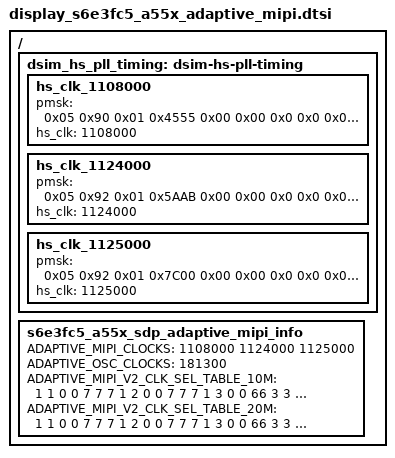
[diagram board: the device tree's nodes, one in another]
/*
 * SAMSUNG Panel Device Tree Source
 *
 * Copyright (c) Samsung Electronics Co., Ltd.
 *		http://www.samsung.com
 *
 * This program is free software; you can redistribute it and/or modify
 * it under the terms of the GNU General Public License version 2 as
 * published by the Free Software Foundation.
 */

#include <dt-bindings/display/rf-band-id.h>

/ {
	fragment@freq_hop {
		target-path = "/";
		__overlay__ {
			dsim_hs_pll_timing: dsim-hs-pll-timing {
				hs_clk_1108000 {
					pmsk = <
						0x05 0x90 0x01 0x4555 /* p m s k */
						0x00 0x00 0x0 0x0
						0x0 0x0 0x0 0x0
						0x0 0x0
						>;
					hs_clk = <1108000>;
				};

				hs_clk_1124000 {
					pmsk = <
						0x05 0x92 0x01 0x5AAB /* p m s k */
						0x00 0x00 0x0 0x0
						0x0 0x0 0x0 0x0
						0x0 0x0
						>;
					hs_clk = <1124000>;
				};

				hs_clk_1125000 {
					pmsk = <
						0x05 0x92 0x01 0x7C00 /* p m s k */
						0x00 0x00 0x0 0x0
						0x0 0x0 0x0 0x0
						0x0 0x0
						>;
					hs_clk = <1125000>;
				};
			};

			s6e3fc5_a55x_sdp_adaptive_mipi_info:
			s6e3fc5_a55x_sdp_adaptive_mipi_info {
				/* TABLE: ADAPTIVE MIPI V2: MIPI CLOCKS [kbps] */
				ADAPTIVE_MIPI_CLOCKS = <
					  1108000
					  1124000
					  1125000
				>;

				/* TABLE: ADAPTIVE MIPI V2: OSC CLOCKS [khz] */
				ADAPTIVE_OSC_CLOCKS = <
					  181300
				>;

				/* TABLE: ADAPTIVE MIPI V2: TABLE_10M */
				/* RAT BAND FROM END RATING_A RATING_B RATING_C */
				ADAPTIVE_MIPI_V2_CLK_SEL_TABLE_10M = <
					1	1	0	0	7	7	7
					1	2	0	0	7	7	7
					1	3	0	0	66	3	3
					1	4	0	0	3	0	0
					2	11	10562	10572	0	60	60
					2	11	10573	10581	0	0	60
					2	11	10582	10583	0	0	0
					2	11	10584	10653	3	0	0
					2	11	10654	10736	0	0	0
					2	11	10737	10746	0	3	0
					2	11	10747	10806	0	3	3
					2	11	10807	10814	0	0	3
					2	11	10815	10816	3	0	3
					2	11	10817	10838	3	0	0
					2	12	9662	9729	60	0	0
					2	12	9730	9799	0	0	0
					2	12	9800	9808	0	60	0
					2	12	9809	9869	0	60	60
					2	12	9870	9878	0	0	60
					2	12	9879	9890	0	0	0
					2	12	9891	9938	3	0	0
					2	13	1162	1162	60	0	0
					2	13	1163	1222	0	0	0
					2	13	1223	1230	0	60	0
					2	13	1231	1292	0	60	60
					2	13	1293	1300	0	0	60
					2	13	1301	1323	0	0	0
					2	13	1324	1393	3	0	0
					2	13	1394	1456	0	0	0
					2	13	1457	1464	0	3	0
					2	13	1465	1513	0	3	3
					2	14	1537	1547	0	60	60
					2	14	1548	1556	0	0	60
					2	14	1557	1558	0	0	0
					2	14	1559	1628	3	0	0
					2	14	1629	1711	0	0	0
					2	14	1712	1721	0	3	0
					2	14	1722	1738	0	3	3
					2	15	4357	4414	7	0	0
					2	15	4415	4418	7	7	0
					2	15	4419	4420	7	7	7
					2	15	4421	4458	0	7	7
					2	16	4387	4413	7	0	0
					2	17	2237	2247	0	2	2
					2	17	2248	2273	40	2	2
					2	17	2274	2284	40	0	2
					2	17	2285	2317	40	0	0
					2	17	2318	2437	0	0	0
					2	17	2438	2449	0	40	0
					2	17	2450	2478	0	40	40
					2	17	2479	2507	2	40	40
					2	17	2508	2519	2	0	40
					2	17	2520	2548	2	0	0
					2	17	2549	2563	0	0	0
					2	18	2937	2948	7	0	0
					2	18	2949	2951	7	7	0
					2	18	2952	2952	0	7	0
					2	18	2953	3018	0	7	7
					2	18	3019	3022	0	0	7
					2	18	3023	3088	0	0	0
					2	29	712	739	7	0	0
					2	29	740	743	7	7	0
					2	29	744	745	7	7	7
					2	29	746	763	0	7	7
					3	91	0	44	0	60	60
					3	91	45	63	0	0	60
					3	91	64	66	0	0	0
					3	91	67	206	3	0	0
					3	91	207	373	0	0	0
					3	91	374	392	0	3	0
					3	91	393	513	0	3	3
					3	91	514	528	0	0	3
					3	91	529	532	3	0	3
					3	91	533	599	3	0	0
					3	92	600	619	0	0	0
					3	92	620	759	60	0	0
					3	92	760	899	0	0	0
					3	92	900	917	0	60	0
					3	92	918	1039	0	60	60
					3	92	1040	1057	0	0	60
					3	92	1058	1081	0	0	0
					3	92	1082	1199	3	0	0
					3	93	1200	1224	60	0	0
					3	93	1225	1344	0	0	0
					3	93	1345	1361	0	60	0
					3	93	1362	1484	0	60	60
					3	93	1485	1501	0	0	60
					3	93	1502	1546	0	0	0
					3	93	1547	1686	3	0	0
					3	93	1687	1813	0	0	0
					3	93	1814	1829	0	3	0
					3	93	1830	1949	0	3	3
					3	94	1950	1994	0	60	60
					3	94	1995	2013	0	0	60
					3	94	2014	2016	0	0	0
					3	94	2017	2156	3	0	0
					3	94	2157	2323	0	0	0
					3	94	2324	2342	0	3	0
					3	94	2343	2399	0	3	3
					3	95	2400	2411	0	0	0
					3	95	2412	2538	7	0	0
					3	95	2539	2546	7	7	0
					3	95	2547	2551	7	7	7
					3	95	2552	2649	0	7	7
					3	97	2750	2794	0	2	2
					3	97	2795	2846	40	2	2
					3	97	2847	2869	40	0	2
					3	97	2870	2934	40	0	0
					3	97	2935	3174	0	0	0
					3	97	3175	3198	0	40	0
					3	97	3199	3256	0	40	40
					3	97	3257	3314	2	40	40
					3	97	3315	3338	2	0	40
					3	97	3339	3396	2	0	0
					3	97	3397	3449	0	0	0
					3	98	3450	3496	7	0	0
					3	98	3497	3503	7	7	0
					3	98	3504	3504	0	7	0
					3	98	3505	3636	0	7	7
					3	98	3637	3644	0	0	7
					3	98	3645	3799	0	0	0
					3	102	5010	5036	0	0	0
					3	102	5037	5143	7	0	0
					3	102	5144	5149	7	7	0
					3	102	5150	5176	7	7	7
					3	102	5177	5179	0	7	7
					3	103	5180	5279	0	7	7
					3	104	5280	5379	0	0	0
					3	107	5730	5813	7	0	0
					3	107	5814	5819	7	7	0
					3	107	5820	5846	7	7	7
					3	107	5847	5849	0	7	7
					3	108	5850	5951	0	0	0
					3	108	5952	5999	7	0	0
					3	109	6000	6078	7	0	0
					3	109	6079	6086	7	7	0
					3	109	6087	6091	7	7	7
					3	109	6092	6149	0	7	7
					3	110	6150	6158	7	7	7
					3	110	6159	6271	0	7	7
					3	110	6272	6278	0	0	7
					3	110	6279	6449	0	0	0
					3	111	6450	6547	0	3	3
					3	111	6548	6560	0	0	3
					3	111	6561	6599	0	0	0
					3	115	8040	8059	0	0	0
					3	115	8060	8199	60	0	0
					3	115	8200	8339	0	0	0
					3	115	8340	8357	0	60	0
					3	115	8358	8479	0	60	60
					3	115	8480	8497	0	0	60
					3	115	8498	8521	0	0	0
					3	115	8522	8661	3	0	0
					3	115	8662	8689	0	0	0
					3	116	8690	8801	0	0	0
					3	116	8802	8928	7	0	0
					3	116	8929	8936	7	7	0
					3	116	8937	8941	7	7	7
					3	116	8942	9039	0	7	7
					3	118	9210	9408	0	0	0
					3	118	9409	9521	7	0	0
					3	118	9522	9528	7	7	0
					3	118	9529	9548	7	7	7
					3	118	9549	9659	0	7	7
					3	119	9660	9769	0	0	0
					3	120	9770	9777	40	0	2
					3	120	9778	9869	40	0	0
					3	122	9920	9988	0	3	3
					3	122	9989	10001	0	0	3
					3	122	10002	10103	0	0	0
					3	122	10104	10243	3	0	0
					3	122	10244	10316	0	0	0
					3	122	10317	10329	0	3	0
					3	122	10330	10359	0	3	3
					3	124	36200	36308	0	3	3
					3	124	36309	36326	0	0	3
					3	124	36327	36343	0	0	0
					3	124	36344	36349	3	0	0
					3	128	37750	37761	0	2	0
					3	128	37762	37833	0	2	2
					3	128	37834	37878	2	2	2
					3	128	37879	37901	2	0	2
					3	128	37902	37973	2	0	0
					3	128	37974	38206	0	0	0
					3	128	38207	38229	0	2	0
					3	128	38230	38249	0	2	2
					3	129	38250	38253	0	3	3
					3	129	38254	38269	0	0	3
					3	129	38270	38308	0	0	0
					3	129	38309	38448	3	0	0
					3	129	38449	38581	0	0	0
					3	129	38582	38598	0	3	0
					3	129	38599	38649	0	3	3
					3	130	38650	38663	0	2	2
					3	130	38664	38668	2	2	2
					3	130	38669	38688	2	0	2
					3	130	38689	38803	2	0	0
					3	130	38804	38996	0	0	0
					3	130	38997	39017	0	2	0
					3	130	39018	39124	0	2	2
					3	130	39125	39136	40	2	2
					3	130	39137	39157	40	0	2
					3	130	39158	39264	40	0	0
					3	130	39265	39464	0	0	0
					3	130	39465	39486	0	40	0
					3	130	39487	39586	0	40	40
					3	130	39587	39604	2	40	40
					3	130	39605	39626	2	0	40
					3	130	39627	39649	2	0	0
					3	131	39650	39689	40	0	0
					3	131	39690	39909	0	0	0
					3	131	39910	39932	0	40	0
					3	131	39933	40011	0	40	40
					3	131	40012	40049	2	40	40
					3	131	40050	40072	2	0	40
					3	131	40073	40151	2	0	0
					3	131	40152	40378	0	0	0
					3	131	40379	40401	0	2	0
					3	131	40402	40473	0	2	2
					3	131	40474	40518	2	2	2
					3	131	40519	40541	2	0	2
					3	131	40542	40613	2	0	0
					3	131	40614	40846	0	0	0
					3	131	40847	40869	0	2	0
					3	131	40870	40934	0	2	2
					3	131	40935	40986	40	2	2
					3	131	40987	41009	40	0	2
					3	131	41010	41074	40	0	0
					3	131	41075	41314	0	0	0
					3	131	41315	41338	0	40	0
					3	131	41339	41396	0	40	40
					3	131	41397	41454	2	40	40
					3	131	41455	41478	2	0	40
					3	131	41479	41536	2	0	0
					3	131	41537	41589	0	0	0
					3	132	41590	41683	0	0	0
					3	132	41684	41708	2	0	0
					3	132	41709	41738	2	2	0
					3	132	41739	41823	2	2	2
					3	132	41824	41848	0	2	2
					3	132	41849	41878	0	0	2
					3	132	41879	42145	0	0	0
					3	132	42146	42176	40	0	0
					3	132	42177	42207	40	2	0
					3	132	42208	42285	40	2	2
					3	132	42286	42316	0	2	2
					3	132	42317	42347	0	0	2
					3	132	42348	42606	0	0	0
					3	132	42607	42645	2	0	0
					3	132	42646	42676	2	40	0
					3	132	42677	42746	2	40	40
					3	132	42747	42785	0	40	40
					3	132	42786	42816	0	0	40
					3	132	42817	43068	0	0	0
					3	132	43069	43113	2	0	0
					3	132	43114	43145	2	2	0
					3	132	43146	43208	2	2	2
					3	132	43209	43253	0	2	2
					3	132	43254	43285	0	0	2
					3	132	43286	43530	0	0	0
					3	132	43531	43581	40	0	0
					3	132	43582	43589	40	2	0
					3	138	55240	55263	2	0	0
					3	138	55264	55295	2	2	0
					3	138	55296	55358	2	2	2
					3	138	55359	55403	0	2	2
					3	138	55404	55435	0	0	2
					3	138	55436	55680	0	0	0
					3	138	55681	55731	40	0	0
					3	138	55732	55763	40	2	0
					3	138	55764	55820	40	2	2
					3	138	55821	55871	0	2	2
					3	138	55872	55903	0	0	2
					3	138	55904	56141	0	0	0
					3	138	56142	56200	2	0	0
					3	138	56201	56232	2	40	0
					3	138	56233	56281	2	40	40
					3	138	56282	56340	0	40	40
					3	138	56341	56372	0	0	40
					3	138	56373	56603	0	0	0
					3	138	56604	56668	2	0	0
					3	138	56669	56701	2	2	0
					3	138	56702	56739	2	2	2
					3	156	66436	66480	0	60	60
					3	156	66481	66499	0	0	60
					3	156	66500	66502	0	0	0
					3	156	66503	66642	3	0	0
					3	156	66643	66809	0	0	0
					3	156	66810	66828	0	3	0
					3	156	66829	66949	0	3	3
					3	156	66950	66964	0	0	3
					3	156	66965	66968	3	0	3
					3	156	66969	67104	3	0	0
					3	156	67105	67277	0	0	0
					3	156	67278	67297	0	3	0
					3	156	67298	67335	0	3	3
					3	161	68586	68809	0	0	0
					3	161	68810	68902	7	0	0
					3	161	68903	68908	7	7	0
					3	161	68909	68935	7	7	7
					4	51	0	0	0	3	3
					4	52	0	0	3	3	3
					4	53	0	0	0	3	6
					4	54	0	0	0	6	6
					4	55	0	0	48	2	4
					4	56	0	0	3	6	6
					5	61	0	0	7	7	7
					5	62	0	0	3	0	0
					5	71	0	0	0	0	0
					7	256	422000	422880	0	60	60
					7	256	422881	423260	0	0	60
					7	256	423261	423320	0	0	0
					7	256	423321	426120	3	0	0
					7	256	426121	429460	0	0	0
					7	256	429461	429840	0	3	0
					7	256	429841	432260	0	3	3
					7	256	432261	432560	0	0	3
					7	256	432561	432640	3	0	3
					7	256	432641	433980	3	0	0
					7	257	386000	386380	0	0	0
					7	257	386381	389180	60	0	0
					7	257	389181	391980	0	0	0
					7	257	391981	392340	0	60	0
					7	257	392341	394780	0	60	60
					7	257	394781	395140	0	0	60
					7	257	395141	395620	0	0	0
					7	257	395621	397980	3	0	0
					7	258	361000	361480	60	0	0
					7	258	361481	363880	0	0	0
					7	258	363881	364220	0	60	0
					7	258	364221	366680	0	60	60
					7	258	366681	367020	0	0	60
					7	258	367021	367920	0	0	0
					7	258	367921	370720	3	0	0
					7	258	370721	373260	0	0	0
					7	258	373261	373580	0	3	0
					7	258	373581	375980	0	3	3
					7	260	173800	174020	0	0	0
					7	260	174021	176560	7	0	0
					7	260	176561	176720	7	7	0
					7	260	176721	176820	7	7	7
					7	260	176821	178780	0	7	7
					7	262	524000	524880	0	2	2
					7	262	524881	525920	40	2	2
					7	262	525921	526380	40	0	2
					7	262	526381	527680	40	0	0
					7	262	527681	532480	0	0	0
					7	262	532481	532960	0	40	0
					7	262	532961	534120	0	40	40
					7	262	534121	535280	2	40	40
					7	262	535281	535760	2	0	40
					7	262	535761	536920	2	0	0
					7	262	536921	538000	0	0	0
					7	263	185000	185920	7	0	0
					7	263	185921	186060	7	7	0
					7	263	186061	186080	0	7	0
					7	263	186081	188720	0	7	7
					7	263	188721	188880	0	0	7
					7	263	188881	191980	0	0	0
					7	267	145800	146320	0	0	0
					7	267	146321	148460	7	0	0
					7	267	148461	148580	7	7	0
					7	267	148581	149120	7	7	7
					7	267	149121	149200	0	7	7
					7	268	149200	151200	0	7	7
					7	269	151600	153580	0	0	0
					7	273	172000	174020	0	0	0
					7	273	174021	175000	7	0	0
					7	275	158200	158360	7	7	7
					7	275	158361	160620	0	7	7
					7	275	160621	160760	0	0	7
					7	275	160761	164180	0	0	0
					7	280	386000	386380	0	0	0
					7	280	386381	389180	60	0	0
					7	280	389181	391980	0	0	0
					7	280	391981	392340	0	60	0
					7	280	392341	394780	0	60	60
					7	280	394781	395140	0	0	60
					7	280	395141	395620	0	0	0
					7	280	395621	398420	3	0	0
					7	280	398421	398980	0	0	0
					7	281	171800	174020	0	0	0
					7	281	174021	176560	7	0	0
					7	281	176561	176720	7	7	0
					7	281	176721	176820	7	7	7
					7	281	176821	178800	0	7	7
					7	283	151600	155560	0	0	0
					7	283	155561	157820	7	0	0
					7	283	157821	157960	7	7	0
					7	283	157961	158360	7	7	7
					7	283	158361	160580	0	7	7
					7	284	143400	145580	0	0	0
					7	285	470000	470140	40	0	2
					7	285	470141	471980	40	0	0
					7	293	514000	514220	0	2	0
					7	293	514221	515660	0	2	2
					7	293	515661	516560	2	2	2
					7	293	516561	517020	2	0	2
					7	293	517021	518460	2	0	0
					7	293	518461	523120	0	0	0
					7	293	523121	523580	0	2	0
					7	293	523581	523980	0	2	2
					7	294	376000	376060	0	3	3
					7	294	376061	376380	0	0	3
					7	294	376381	377160	0	0	0
					7	294	377161	379960	3	0	0
					7	294	379961	382620	0	0	0
					7	294	382621	382960	0	3	0
					7	294	382961	384000	0	3	3
					7	295	460000	460260	0	2	2
					7	295	460261	460360	2	2	2
					7	295	460361	460760	2	0	2
					7	295	460761	463060	2	0	0
					7	295	463061	466920	0	0	0
					7	295	466921	467340	0	2	0
					7	295	467341	469480	0	2	2
					7	295	469481	469720	40	2	2
					7	295	469721	470140	40	0	2
					7	295	470141	472280	40	0	0
					7	295	472281	476280	0	0	0
					7	295	476281	476720	0	40	0
					7	295	476721	478720	0	40	40
					7	295	478721	479080	2	40	40
					7	295	479081	479520	2	0	40
					7	295	479521	480000	2	0	0
					7	296	499200	499980	40	0	0
					7	296	499981	504380	0	0	0
					7	296	504381	504840	0	40	0
					7	296	504841	506420	0	40	40
					7	296	506421	507180	2	40	40
					7	296	507181	507640	2	0	40
					7	296	507641	509220	2	0	0
					7	296	509221	513760	0	0	0
					7	296	513761	514220	0	2	0
					7	296	514221	515660	0	2	2
					7	296	515661	516560	2	2	2
					7	296	516561	517020	2	0	2
					7	296	517021	518460	2	0	0
					7	296	518461	523120	0	0	0
					7	296	523121	523580	0	2	0
					7	296	523581	524880	0	2	2
					7	296	524881	525920	40	2	2
					7	296	525921	526380	40	0	2
					7	296	526381	527680	40	0	0
					7	296	527681	532480	0	0	0
					7	296	532481	532960	0	40	0
					7	296	532961	534120	0	40	40
					7	296	534121	535280	2	40	40
					7	296	535281	535760	2	0	40
					7	296	535761	536920	2	0	0
					7	296	536921	537980	0	0	0
					7	303	636667	636807	1	0	0
					7	303	636808	637027	1	1	0
					7	303	637028	637447	1	1	1
					7	303	637448	637747	0	1	1
					7	303	637748	637947	0	0	1
					7	303	637948	639587	0	0	0
					7	303	639588	639927	20	0	0
					7	303	639928	640147	20	1	0
					7	303	640148	640527	20	1	1
					7	303	640528	640867	0	1	1
					7	303	640868	641087	0	0	1
					7	303	641088	642667	0	0	0
					7	303	642668	643067	1	0	0
					7	303	643068	643267	1	20	0
					7	303	643268	643607	1	20	20
					7	303	643608	643987	0	20	20
					7	303	643988	644207	0	0	20
					7	303	644208	645747	0	0	0
					7	303	645748	646187	1	0	0
					7	303	646188	646407	1	1	0
					7	303	646408	646666	1	1	1
					7	321	422000	422880	0	60	60
					7	321	422881	423260	0	0	60
					7	321	423261	423320	0	0	0
					7	321	423321	426120	3	0	0
					7	321	426121	429460	0	0	0
					7	321	429461	429840	0	3	0
					7	321	429841	432260	0	3	3
					7	321	432261	432560	0	0	3
					7	321	432561	432640	3	0	3
					7	321	432641	435360	3	0	0
					7	321	435361	438820	0	0	0
					7	321	438821	439220	0	3	0
					7	321	439221	439980	0	3	3
					7	326	123400	127860	0	0	0
					7	326	127861	129720	7	0	0
					7	326	129721	129840	7	7	0
					7	326	129841	130380	7	7	7
					7	332	620000	621120	0	0	0
					7	332	621121	621200	20	0	0
					7	332	621201	621400	20	1	0
					7	332	621401	622060	20	1	1
					7	332	622061	622140	0	1	1
					7	332	622141	622340	0	0	1
					7	332	622341	624200	0	0	0
					7	332	624201	624320	1	0	0
					7	332	624321	624520	1	20	0
					7	332	624521	625140	1	20	20
					7	332	625141	625260	0	20	20
					7	332	625261	625460	0	0	20
					7	332	625461	627280	0	0	0
					7	332	627281	627440	1	0	0
					7	332	627441	627640	1	1	0
					7	332	627641	628220	1	1	1
					7	332	628221	628380	0	1	1
					7	332	628381	628580	0	0	1
					7	332	628581	630360	0	0	0
					7	332	630361	630560	20	0	0
					7	332	630561	630780	20	1	0
					7	332	630781	631280	20	1	1
					7	332	631281	631500	0	1	1
					7	332	631501	631700	0	0	1
					7	332	631701	633440	0	0	0
					7	332	633441	633700	1	0	0
					7	332	633701	633900	1	20	0
					7	332	633901	634360	1	20	20
					7	332	634361	634620	0	20	20
					7	332	634621	634840	0	0	20
					7	332	634841	636520	0	0	0
					7	332	636521	636820	1	0	0
					7	332	636821	637020	1	1	0
					7	332	637021	637440	1	1	1
					7	332	637441	637740	0	1	1
					7	332	637741	637960	0	0	1
					7	332	637961	639600	0	0	0
					7	332	639601	639940	20	0	0
					7	332	639941	640140	20	1	0
					7	332	640141	640520	20	1	1
					7	332	640521	640860	0	1	1
					7	332	640861	641080	0	0	1
					7	332	641081	642660	0	0	0
					7	332	642661	643060	1	0	0
					7	332	643061	643280	1	20	0
					7	332	643281	643600	1	20	20
					7	332	643601	643980	0	20	20
					7	332	643981	644200	0	0	20
					7	332	644201	645740	0	0	0
					7	332	645741	646180	1	0	0
					7	332	646181	646400	1	1	0
					7	332	646401	646680	1	1	1
					7	332	646681	647120	0	1	1
					7	332	647121	647340	0	0	1
					7	332	647341	648820	0	0	0
					7	332	648821	649300	20	0	0
					7	332	649301	649520	20	1	0
					7	332	649521	649760	20	1	1
					7	332	649761	650240	0	1	1
					7	332	650241	650460	0	0	1
					7	332	650461	651900	0	0	0
					7	332	651901	652420	1	0	0
					7	332	652421	652640	1	20	0
					7	332	652641	652840	1	20	20
					7	332	652841	653360	0	20	20
					7	332	653361	653580	0	0	20
					7	332	653581	654980	0	0	0
					7	332	654981	655540	1	0	0
					7	332	655541	655780	1	1	0
					7	332	655781	655920	1	1	1
					7	332	655921	656480	0	1	1
					7	332	656481	656700	0	0	1
					7	332	656701	658060	0	0	0
					7	332	658061	658660	20	0	0
					7	332	658661	658900	20	1	0
					7	332	658901	658980	20	1	1
					7	332	658981	659600	0	1	1
					7	332	659601	659840	0	0	1
					7	332	659841	661140	0	0	0
					7	332	661141	661800	1	0	0
					7	332	661801	662020	1	20	0
					7	332	662021	662060	1	20	20
					7	332	662061	662720	0	20	20
					7	332	662721	662960	0	0	20
					7	332	662961	664220	0	0	0
					7	332	664221	664920	1	0	0
					7	332	664921	665140	1	1	0
					7	332	665141	665840	0	1	1
					7	332	665841	666080	0	0	1
					7	332	666081	667300	0	0	0
					7	332	667301	668040	20	0	0
					7	332	668041	668220	20	1	0
					7	332	668221	668280	0	1	0
					7	332	668281	668960	0	1	1
					7	332	668961	669200	0	0	1
					7	332	669201	670360	0	0	0
					7	332	670361	671160	1	0	0
					7	332	671161	671300	1	20	0
					7	332	671301	671400	0	20	0
					7	332	671401	672080	0	20	20
					7	332	672081	672340	0	0	20
					7	332	672341	673440	0	0	0
					7	332	673441	674280	1	0	0
					7	332	674281	674380	1	1	0
					7	332	674381	674520	0	1	0
					7	332	674521	675220	0	1	1
					7	332	675221	675460	0	0	1
					7	332	675461	676520	0	0	0
					7	332	676521	677400	20	0	0
					7	332	677401	677460	20	1	0
					7	332	677461	677640	0	1	0
					7	332	677641	678340	0	1	1
					7	332	678341	678580	0	0	1
					7	332	678581	679600	0	0	0
					7	332	679601	680000	1	0	0
					7	333	620000	621120	0	0	0
					7	333	621121	621200	20	0	0
					7	333	621201	621400	20	1	0
					7	333	621401	622060	20	1	1
					7	333	622061	622140	0	1	1
					7	333	622141	622340	0	0	1
					7	333	622341	624200	0	0	0
					7	333	624201	624320	1	0	0
					7	333	624321	624520	1	20	0
					7	333	624521	625140	1	20	20
					7	333	625141	625260	0	20	20
					7	333	625261	625460	0	0	20
					7	333	625461	627280	0	0	0
					7	333	627281	627440	1	0	0
					7	333	627441	627640	1	1	0
					7	333	627641	628220	1	1	1
					7	333	628221	628380	0	1	1
					7	333	628381	628580	0	0	1
					7	333	628581	630360	0	0	0
					7	333	630361	630560	20	0	0
					7	333	630561	630780	20	1	0
					7	333	630781	631280	20	1	1
					7	333	631281	631500	0	1	1
					7	333	631501	631700	0	0	1
					7	333	631701	633440	0	0	0
					7	333	633441	633700	1	0	0
					7	333	633701	633900	1	20	0
					7	333	633901	634360	1	20	20
					7	333	634361	634620	0	20	20
					7	333	634621	634840	0	0	20
					7	333	634841	636520	0	0	0
					7	333	636521	636820	1	0	0
					7	333	636821	637020	1	1	0
					7	333	637021	637440	1	1	1
					7	333	637441	637740	0	1	1
					7	333	637741	637960	0	0	1
					7	333	637961	639600	0	0	0
					7	333	639601	639940	20	0	0
					7	333	639941	640140	20	1	0
					7	333	640141	640520	20	1	1
					7	333	640521	640860	0	1	1
					7	333	640861	641080	0	0	1
					7	333	641081	642660	0	0	0
					7	333	642661	643060	1	0	0
					7	333	643061	643280	1	20	0
					7	333	643281	643600	1	20	20
					7	333	643601	643980	0	20	20
					7	333	643981	644200	0	0	20
					7	333	644201	645740	0	0	0
					7	333	645741	646180	1	0	0
					7	333	646181	646400	1	1	0
					7	333	646401	646680	1	1	1
					7	333	646681	647120	0	1	1
					7	333	647121	647340	0	0	1
					7	333	647341	648820	0	0	0
					7	333	648821	649300	20	0	0
					7	333	649301	649520	20	1	0
					7	333	649521	649760	20	1	1
					7	333	649761	650240	0	1	1
					7	333	650241	650460	0	0	1
					7	333	650461	651900	0	0	0
					7	333	651901	652420	1	0	0
					7	333	652421	652640	1	20	0
					7	333	652641	652840	1	20	20
					7	333	652841	653333	0	20	20
					7	334	693334	693954	0	1	1
					7	334	693955	694214	0	0	1
					7	334	694215	694994	0	0	0
					7	334	694995	695914	20	0	0
					7	334	695915	696134	0	0	0
					7	334	696135	696394	0	1	0
					7	334	696395	697074	0	1	1
					7	334	697075	697334	0	0	1
					7	334	697335	698074	0	0	0
					7	334	698075	698994	1	0	0
					7	334	698995	699254	0	0	0
					7	334	699255	699534	0	20	0
					7	334	699535	700194	0	20	20
					7	334	700195	700454	0	0	20
					7	334	700455	701154	0	0	0
					7	334	701155	702074	1	0	0
					7	334	702075	702374	0	0	0
					7	334	702375	702654	0	1	0
					7	334	702655	703314	0	1	1
					7	334	703315	703574	0	0	1
					7	334	703575	704234	0	0	0
					7	334	704235	705154	20	0	0
					7	334	705155	705494	0	0	0
					7	334	705495	705774	0	1	0
					7	334	705775	706434	0	1	1
					7	334	706435	706714	0	0	1
					7	334	706715	707294	0	0	0
					7	334	707295	708234	1	0	0
					7	334	708235	708634	0	0	0
					7	334	708635	708894	0	20	0
					7	334	708895	709554	0	20	20
					7	334	709555	709834	0	0	20
					7	334	709835	710374	0	0	0
					7	334	710375	711314	1	0	0
					7	334	711315	711754	0	0	0
					7	334	711755	712034	0	1	0
					7	334	712035	712674	0	1	1
					7	334	712675	712954	0	0	1
					7	334	712955	713454	0	0	0
					7	334	713455	714394	20	0	0
					7	334	714395	714874	0	0	0
					7	334	714875	715154	0	1	0
					7	334	715155	715794	0	1	1
					7	334	715795	716074	0	0	1
					7	334	716075	716534	0	0	0
					7	334	716535	717474	1	0	0
					7	334	717475	717994	0	0	0
					7	334	717995	718274	0	20	0
					7	334	718275	718914	0	20	20
					7	334	718915	719214	0	0	20
					7	334	719215	719614	0	0	0
					7	334	719615	720554	1	0	0
					7	334	720555	721114	0	0	0
					7	334	721115	721394	0	1	0
					7	334	721395	722054	0	1	1
					7	334	722055	722334	0	0	1
					7	334	722335	722694	0	0	0
					7	334	722695	723614	20	0	0
					7	334	723615	724234	0	0	0
					7	334	724235	724534	0	1	0
					7	334	724535	725174	0	1	1
					7	334	725175	725454	0	0	1
					7	334	725455	725774	0	0	0
					7	334	725775	726694	1	0	0
					7	334	726695	727354	0	0	0
					7	334	727355	727654	0	20	0
					7	334	727655	728294	0	20	20
					7	334	728295	728574	0	0	20
					7	334	728575	728854	0	0	0
					7	334	728855	729774	1	0	0
					7	334	729775	730474	0	0	0
					7	334	730475	730774	0	1	0
					7	334	730775	731414	0	1	1
					7	334	731415	731714	0	0	1
					7	334	731715	731934	0	0	0
					7	334	731935	732854	20	0	0
					7	334	732855	733333	0	0	0
				>;

				/* TABLE: ADAPTIVE MIPI V2: TABLE_20M */
				/* RAT BAND FROM END RATING_A RATING_B RATING_C */
				ADAPTIVE_MIPI_V2_CLK_SEL_TABLE_20M = <
					1	1	0	0	7	7	7
					1	2	0	0	7	7	7
					1	3	0	0	66	3	3
					1	4	0	0	3	0	0
					2	11	10562	10572	0	60	60
					2	11	10573	10581	0	0	60
					2	11	10582	10583	0	0	0
					2	11	10584	10653	3	0	0
					2	11	10654	10736	0	0	0
					2	11	10737	10746	0	3	0
					2	11	10747	10806	0	3	3
					2	11	10807	10814	0	0	3
					2	11	10815	10816	3	0	3
					2	11	10817	10838	3	0	0
					2	12	9662	9729	60	0	0
					2	12	9730	9799	0	0	0
					2	12	9800	9808	0	60	0
					2	12	9809	9869	0	60	60
					2	12	9870	9878	0	0	60
					2	12	9879	9890	0	0	0
					2	12	9891	9938	3	0	0
					2	13	1162	1162	60	0	0
					2	13	1163	1222	0	0	0
					2	13	1223	1230	0	60	0
					2	13	1231	1292	0	60	60
					2	13	1293	1300	0	0	60
					2	13	1301	1323	0	0	0
					2	13	1324	1393	3	0	0
					2	13	1394	1456	0	0	0
					2	13	1457	1464	0	3	0
					2	13	1465	1513	0	3	3
					2	14	1537	1547	0	60	60
					2	14	1548	1556	0	0	60
					2	14	1557	1558	0	0	0
					2	14	1559	1628	3	0	0
					2	14	1629	1711	0	0	0
					2	14	1712	1721	0	3	0
					2	14	1722	1738	0	3	3
					2	15	4357	4414	7	0	0
					2	15	4415	4418	7	7	0
					2	15	4419	4420	7	7	7
					2	15	4421	4458	0	7	7
					2	16	4387	4413	7	0	0
					2	17	2237	2247	0	2	2
					2	17	2248	2273	40	2	2
					2	17	2274	2284	40	0	2
					2	17	2285	2317	40	0	0
					2	17	2318	2437	0	0	0
					2	17	2438	2449	0	40	0
					2	17	2450	2478	0	40	40
					2	17	2479	2507	2	40	40
					2	17	2508	2519	2	0	40
					2	17	2520	2548	2	0	0
					2	17	2549	2563	0	0	0
					2	18	2937	2948	7	0	0
					2	18	2949	2951	7	7	0
					2	18	2952	2952	0	7	0
					2	18	2953	3018	0	7	7
					2	18	3019	3022	0	0	7
					2	18	3023	3088	0	0	0
					2	29	712	739	7	0	0
					2	29	740	743	7	7	0
					2	29	744	745	7	7	7
					2	29	746	763	0	7	7
					3	91	0	16	0	60	60
					3	91	17	94	3	60	60
					3	91	95	113	3	0	60
					3	91	114	256	3	0	0
					3	91	257	323	0	0	0
					3	91	324	342	0	3	0
					3	91	343	478	0	3	3
					3	91	479	563	3	3	3
					3	91	564	582	3	0	3
					3	91	583	599	3	0	0
					3	92	600	621	60	3	3
					3	92	622	638	60	0	3
					3	92	639	809	60	0	0
					3	92	810	849	0	0	0
					3	92	850	867	0	60	0
					3	92	868	1031	0	60	60
					3	92	1032	1089	3	60	60
					3	92	1090	1107	3	0	60
					3	92	1108	1199	3	0	0
					3	93	1200	1274	60	0	0
					3	93	1275	1294	0	0	0
					3	93	1295	1311	0	60	0
					3	93	1312	1496	0	60	60
					3	93	1497	1534	3	60	60
					3	93	1535	1551	3	0	60
					3	93	1552	1736	3	0	0
					3	93	1737	1763	0	0	0
					3	93	1764	1779	0	3	0
					3	93	1780	1949	0	3	3
					3	94	1950	1966	0	60	60
					3	94	1967	2044	3	60	60
					3	94	2045	2063	3	0	60
					3	94	2064	2206	3	0	0
					3	94	2207	2273	0	0	0
					3	94	2274	2292	0	3	0
					3	94	2293	2399	0	3	3
					3	95	2400	2488	7	0	0
					3	95	2489	2496	7	7	0
					3	95	2497	2601	7	7	7
					3	95	2602	2649	0	7	7
					3	97	2750	2896	40	2	2
					3	97	2897	2919	40	0	2
					3	97	2920	2984	40	0	0
					3	97	2985	3124	0	0	0
					3	97	3125	3148	0	40	0
					3	97	3149	3206	0	40	40
					3	97	3207	3364	2	40	40
					3	97	3365	3388	2	0	40
					3	97	3389	3446	2	0	0
					3	97	3447	3449	0	0	0
					3	98	3450	3454	7	7	0
					3	98	3455	3553	7	7	7
					3	98	3554	3686	0	7	7
					3	98	3687	3694	0	0	7
					3	98	3695	3774	0	0	0
					3	98	3775	3799	140	0	0
					3	102	5010	5093	7	0	0
					3	102	5094	5099	7	7	0
					3	102	5100	5179	7	7	7
					3	103	5180	5226	7	7	7
					3	103	5227	5279	0	7	7
					3	104	5280	5313	0	7	7
					3	104	5314	5319	0	0	7
					3	104	5320	5379	0	0	0
					3	107	5730	5763	7	0	0
					3	107	5764	5769	7	7	0
					3	107	5770	5849	7	7	7
					3	108	5850	5901	0	0	0
					3	108	5902	5999	7	0	0
					3	109	6000	6028	7	0	0
					3	109	6029	6036	7	7	0
					3	109	6037	6141	7	7	7
					3	109	6142	6149	0	7	7
					3	110	6150	6208	7	7	7
					3	110	6209	6321	0	7	7
					3	110	6322	6328	0	0	7
					3	110	6329	6429	0	0	0
					3	110	6430	6449	140	0	0
					3	111	6450	6597	0	3	3
					3	111	6598	6599	0	0	3
					3	115	8040	8061	60	3	3
					3	115	8062	8078	60	0	3
					3	115	8079	8249	60	0	0
					3	115	8250	8289	0	0	0
					3	115	8290	8307	0	60	0
					3	115	8308	8471	0	60	60
					3	115	8472	8529	3	60	60
					3	115	8530	8547	3	0	60
					3	115	8548	8689	3	0	0
					3	116	8690	8751	0	0	0
					3	116	8752	8878	7	0	0
					3	116	8879	8886	7	7	0
					3	116	8887	8991	7	7	7
					3	116	8992	9039	0	7	7
					3	118	9210	9243	0	7	7
					3	118	9244	9249	0	0	7
					3	118	9250	9358	0	0	0
					3	118	9359	9471	7	0	0
					3	118	9472	9478	7	7	0
					3	118	9479	9598	7	7	7
					3	118	9599	9659	0	7	7
					3	119	9660	9756	0	0	0
					3	119	9757	9769	7	0	0
					3	120	9770	9806	40	2	2
					3	120	9807	9827	40	0	2
					3	120	9828	9869	40	0	0
					3	122	9920	10038	0	3	3
					3	122	10039	10051	0	0	3
					3	122	10052	10053	0	0	0
					3	122	10054	10266	3	0	0
					3	122	10267	10279	3	3	0
					3	122	10280	10293	3	3	3
					3	122	10294	10359	0	3	3
					3	124	36200	36293	0	3	3
					3	124	36294	36349	3	3	3
					3	128	37750	37783	0	2	2
					3	128	37784	37928	2	2	2
					3	128	37929	37951	2	0	2
					3	128	37952	38023	2	0	0
					3	128	38024	38156	0	0	0
					3	128	38157	38179	0	2	0
					3	128	38180	38244	0	2	2
					3	128	38245	38249	40	2	2
					3	129	38250	38258	0	3	3
					3	129	38259	38303	3	3	3
					3	129	38304	38319	3	0	3
					3	129	38320	38498	3	0	0
					3	129	38499	38531	0	0	0
					3	129	38532	38548	0	3	0
					3	129	38549	38649	0	3	3
					3	130	38650	38718	2	2	2
					3	130	38719	38738	2	0	2
					3	130	38739	38853	2	0	0
					3	130	38854	38946	0	0	0
					3	130	38947	38967	0	2	0
					3	130	38968	39074	0	2	2
					3	130	39075	39186	40	2	2
					3	130	39187	39207	40	0	2
					3	130	39208	39314	40	0	0
					3	130	39315	39414	0	0	0
					3	130	39415	39436	0	40	0
					3	130	39437	39536	0	40	40
					3	130	39537	39649	2	40	40
					3	131	39650	39653	40	0	2
					3	131	39654	39739	40	0	0
					3	131	39740	39859	0	0	0
					3	131	39860	39882	0	40	0
					3	131	39883	39961	0	40	40
					3	131	39962	40099	2	40	40
					3	131	40100	40122	2	0	40
					3	131	40123	40201	2	0	0
					3	131	40202	40328	0	0	0
					3	131	40329	40351	0	2	0
					3	131	40352	40423	0	2	2
					3	131	40424	40568	2	2	2
					3	131	40569	40591	2	0	2
					3	131	40592	40663	2	0	0
					3	131	40664	40796	0	0	0
					3	131	40797	40819	0	2	0
					3	131	40820	40884	0	2	2
					3	131	40885	41036	40	2	2
					3	131	41037	41059	40	0	2
					3	131	41060	41124	40	0	0
					3	131	41125	41264	0	0	0
					3	131	41265	41288	0	40	0
					3	131	41289	41346	0	40	40
					3	131	41347	41504	2	40	40
					3	131	41505	41528	2	0	40
					3	131	41529	41586	2	0	0
					3	131	41587	41589	0	0	0
					3	132	41590	41633	0	0	0
					3	132	41634	41658	2	0	0
					3	132	41659	41688	2	2	0
					3	132	41689	41873	2	2	2
					3	132	41874	41898	0	2	2
					3	132	41899	41928	0	0	2
					3	132	41929	42095	0	0	0
					3	132	42096	42126	40	0	0
					3	132	42127	42157	40	2	0
					3	132	42158	42335	40	2	2
					3	132	42336	42366	0	2	2
					3	132	42367	42397	0	0	2
					3	132	42398	42556	0	0	0
					3	132	42557	42595	2	0	0
					3	132	42596	42626	2	40	0
					3	132	42627	42796	2	40	40
					3	132	42797	42835	0	40	40
					3	132	42836	42866	0	0	40
					3	132	42867	43018	0	0	0
					3	132	43019	43063	2	0	0
					3	132	43064	43095	2	2	0
					3	132	43096	43258	2	2	2
					3	132	43259	43303	0	2	2
					3	132	43304	43335	0	0	2
					3	132	43336	43480	0	0	0
					3	132	43481	43531	40	0	0
					3	132	43532	43563	40	2	0
					3	132	43564	43589	40	2	2
					3	138	55240	55245	2	2	0
					3	138	55246	55408	2	2	2
					3	138	55409	55453	0	2	2
					3	138	55454	55485	0	0	2
					3	138	55486	55630	0	0	0
					3	138	55631	55681	40	0	0
					3	138	55682	55713	40	2	0
					3	138	55714	55870	40	2	2
					3	138	55871	55921	0	2	2
					3	138	55922	55953	0	0	2
					3	138	55954	56091	0	0	0
					3	138	56092	56150	2	0	0
					3	138	56151	56182	2	40	0
					3	138	56183	56331	2	40	40
					3	138	56332	56390	0	40	40
					3	138	56391	56422	0	0	40
					3	138	56423	56553	0	0	0
					3	138	56554	56618	2	0	0
					3	138	56619	56651	2	2	0
					3	138	56652	56739	2	2	2
					3	156	66436	66452	0	60	60
					3	156	66453	66530	3	60	60
					3	156	66531	66549	3	0	60
					3	156	66550	66692	3	0	0
					3	156	66693	66759	0	0	0
					3	156	66760	66778	0	3	0
					3	156	66779	66914	0	3	3
					3	156	66915	66999	3	3	3
					3	156	67000	67018	3	0	3
					3	156	67019	67154	3	0	0
					3	156	67155	67227	0	0	0
					3	156	67228	67247	0	3	0
					3	156	67248	67335	0	3	3
					3	161	68586	68624	0	7	7
					3	161	68625	68629	0	0	7
					3	161	68630	68759	0	0	0
					3	161	68760	68852	7	0	0
					3	161	68853	68858	7	7	0
					3	161	68859	68935	7	7	7
					4	51	0	0	0	3	3
					4	52	0	0	3	3	3
					4	53	0	0	0	3	6
					4	54	0	0	21	6	6
					4	55	0	0	48	46	46
					4	56	0	0	3	6	6
					5	61	0	0	7	7	7
					5	62	0	0	3	0	0
					5	71	0	0	0	0	0
					7	256	422000	422320	0	60	60
					7	256	422321	423880	3	60	60
					7	256	423881	424260	3	0	60
					7	256	424261	427120	3	0	0
					7	256	427121	428460	0	0	0
					7	256	428461	428840	0	3	0
					7	256	428841	431560	0	3	3
					7	256	431561	433260	3	3	3
					7	256	433261	433640	3	0	3
					7	256	433641	433980	3	0	0
					7	257	386000	386420	60	3	3
					7	257	386421	386760	60	0	3
					7	257	386761	390180	60	0	0
					7	257	390181	390980	0	0	0
					7	257	390981	391340	0	60	0
					7	257	391341	394620	0	60	60
					7	257	394621	395780	3	60	60
					7	257	395781	396140	3	0	60
					7	257	396141	397980	3	0	0
					7	258	361000	362480	60	0	0
					7	258	362481	362880	0	0	0
					7	258	362881	363220	0	60	0
					7	258	363221	366920	0	60	60
					7	258	366921	367680	3	60	60
					7	258	367681	368020	3	0	60
					7	258	368021	371720	3	0	0
					7	258	371721	372260	0	0	0
					7	258	372261	372580	0	3	0
					7	258	372581	375980	0	3	3
					7	260	173800	175560	7	0	0
					7	260	175561	175720	7	7	0
					7	260	175721	177820	7	7	7
					7	260	177821	178780	0	7	7
					7	262	524000	526920	40	2	2
					7	262	526921	527380	40	0	2
					7	262	527381	528680	40	0	0
					7	262	528681	531480	0	0	0
					7	262	531481	531960	0	40	0
					7	262	531961	533120	0	40	40
					7	262	533121	536280	2	40	40
					7	262	536281	536760	2	0	40
					7	262	536761	537920	2	0	0
					7	262	537921	538000	0	0	0
					7	263	185000	185080	7	7	0
					7	263	185081	187060	7	7	7
					7	263	187061	189720	0	7	7
					7	263	189721	189880	0	0	7
					7	263	189881	191480	0	0	0
					7	263	191481	191980	140	0	0
					7	267	145800	147460	7	0	0
					7	267	147461	147580	7	7	0
					7	267	147581	149200	7	7	7
					7	268	149200	150120	7	7	7
					7	268	150121	151200	0	7	7
					7	269	151600	152260	0	7	7
					7	269	152261	152380	0	0	7
					7	269	152381	153580	0	0	0
					7	273	172000	173020	0	0	0
					7	273	173021	175000	7	0	0
					7	275	158200	159360	7	7	7
					7	275	159361	161620	0	7	7
					7	275	161621	161760	0	0	7
					7	275	161761	163780	0	0	0
					7	275	163781	164180	140	0	0
					7	280	386000	386420	60	3	3
					7	280	386421	386760	60	0	3
					7	280	386761	390180	60	0	0
					7	280	390181	390980	0	0	0
					7	280	390981	391340	0	60	0
					7	280	391341	394620	0	60	60
					7	280	394621	395780	3	60	60
					7	280	395781	396140	3	0	60
					7	280	396141	398980	3	0	0
					7	281	171800	173020	0	0	0
					7	281	173021	175560	7	0	0
					7	281	175561	175720	7	7	0
					7	281	175721	177820	7	7	7
					7	281	177821	178800	0	7	7
					7	283	151600	152260	0	7	7
					7	283	152261	152380	0	0	7
					7	283	152381	154560	0	0	0
					7	283	154561	156820	7	0	0
					7	283	156821	156960	7	7	0
					7	283	156961	159360	7	7	7
					7	283	159361	160580	0	7	7
					7	284	143400	145320	0	0	0
					7	284	145321	145580	7	0	0
					7	285	470000	470720	40	2	2
					7	285	470721	471140	40	0	2
					7	285	471141	471980	40	0	0
					7	293	514000	514660	0	2	2
					7	293	514661	517560	2	2	2
					7	293	517561	518020	2	0	2
					7	293	518021	519460	2	0	0
					7	293	519461	522120	0	0	0
					7	293	522121	522580	0	2	0
					7	293	522581	523880	0	2	2
					7	293	523881	523980	40	2	2
					7	294	376000	376160	0	3	3
					7	294	376161	377060	3	3	3
					7	294	377061	377380	3	0	3
					7	294	377381	380960	3	0	0
					7	294	380961	381620	0	0	0
					7	294	381621	381960	0	3	0
					7	294	381961	384000	0	3	3
					7	295	460000	461360	2	2	2
					7	295	461361	461760	2	0	2
					7	295	461761	464060	2	0	0
					7	295	464061	465920	0	0	0
					7	295	465921	466340	0	2	0
					7	295	466341	468480	0	2	2
					7	295	468481	470720	40	2	2
					7	295	470721	471140	40	0	2
					7	295	471141	473280	40	0	0
					7	295	473281	475280	0	0	0
					7	295	475281	475720	0	40	0
					7	295	475721	477720	0	40	40
					7	295	477721	480000	2	40	40
					7	296	499200	499260	40	0	2
					7	296	499261	500980	40	0	0
					7	296	500981	503380	0	0	0
					7	296	503381	503840	0	40	0
					7	296	503841	505420	0	40	40
					7	296	505421	508180	2	40	40
					7	296	508181	508640	2	0	40
					7	296	508641	510220	2	0	0
					7	296	510221	512760	0	0	0
					7	296	512761	513220	0	2	0
					7	296	513221	514660	0	2	2
					7	296	514661	517560	2	2	2
					7	296	517561	518020	2	0	2
					7	296	518021	519460	2	0	0
					7	296	519461	522120	0	0	0
					7	296	522121	522580	0	2	0
					7	296	522581	523880	0	2	2
					7	296	523881	526920	40	2	2
					7	296	526921	527380	40	0	2
					7	296	527381	528680	40	0	0
					7	296	528681	531480	0	0	0
					7	296	531481	531960	0	40	0
					7	296	531961	533120	0	40	40
					7	296	533121	536280	2	40	40
					7	296	536281	536760	2	0	40
					7	296	536761	537920	2	0	0
					7	296	537921	537980	0	0	0
					7	303	636667	636687	1	1	0
					7	303	636688	637787	1	1	1
					7	303	637788	638087	0	1	1
					7	303	638088	638287	0	0	1
					7	303	638288	639267	0	0	0
					7	303	639268	639607	20	0	0
					7	303	639608	639807	20	1	0
					7	303	639808	640847	20	1	1
					7	303	640848	641207	0	1	1
					7	303	641208	641407	0	0	1
					7	303	641408	642327	0	0	0
					7	303	642328	642727	1	0	0
					7	303	642728	642947	1	20	0
					7	303	642948	643927	1	20	20
					7	303	643928	644327	0	20	20
					7	303	644328	644547	0	0	20
					7	303	644548	645407	0	0	0
					7	303	645408	645847	1	0	0
					7	303	645848	646067	1	1	0
					7	303	646068	646666	1	1	1
					7	321	422000	422320	0	60	60
					7	321	422321	423880	3	60	60
					7	321	423881	424260	3	0	60
					7	321	424261	427120	3	0	0
					7	321	427121	428460	0	0	0
					7	321	428461	428840	0	3	0
					7	321	428841	431560	0	3	3
					7	321	431561	433260	3	3	3
					7	321	433261	433640	3	0	3
					7	321	433641	436360	3	0	0
					7	321	436361	437820	0	0	0
					7	321	437821	438220	0	3	0
					7	321	438221	439980	0	3	3
					7	326	123400	124160	0	7	7
					7	326	124161	124260	0	0	7
					7	326	124261	126860	0	0	0
					7	326	126861	128720	7	0	0
					7	326	128721	128840	7	7	0
					7	326	128841	130380	7	7	7
					7	332	620000	620800	0	0	0
					7	332	620801	620860	20	0	0
					7	332	620861	621060	20	1	0
					7	332	621061	622380	20	1	1
					7	332	622381	622460	0	1	1
					7	332	622461	622660	0	0	1
					7	332	622661	623860	0	0	0
					7	332	623861	624000	1	0	0
					7	332	624001	624200	1	20	0
					7	332	624201	625460	1	20	20
					7	332	625461	625580	0	20	20
					7	332	625581	625780	0	0	20
					7	332	625781	626940	0	0	0
					7	332	626941	627120	1	0	0
					7	332	627121	627320	1	1	0
					7	332	627321	628540	1	1	1
					7	332	628541	628720	0	1	1
					7	332	628721	628920	0	0	1
					7	332	628921	630020	0	0	0
					7	332	630021	630240	20	0	0
					7	332	630241	630440	20	1	0
					7	332	630441	631620	20	1	1
					7	332	631621	631840	0	1	1
					7	332	631841	632040	0	0	1
					7	332	632041	633100	0	0	0
					7	332	633101	633360	1	0	0
					7	332	633361	633560	1	20	0
					7	332	633561	634700	1	20	20
					7	332	634701	634960	0	20	20
					7	332	634961	635160	0	0	20
					7	332	635161	636180	0	0	0
					7	332	636181	636480	1	0	0
					7	332	636481	636700	1	1	0
					7	332	636701	637780	1	1	1
					7	332	637781	638080	0	1	1
					7	332	638081	638280	0	0	1
					7	332	638281	639260	0	0	0
					7	332	639261	639600	20	0	0
					7	332	639601	639820	20	1	0
					7	332	639821	640860	20	1	1
					7	332	640861	641200	0	1	1
					7	332	641201	641420	0	0	1
					7	332	641421	642340	0	0	0
					7	332	642341	642720	1	0	0
					7	332	642721	642940	1	20	0
					7	332	642941	643940	1	20	20
					7	332	643941	644320	0	20	20
					7	332	644321	644540	0	0	20
					7	332	644541	645420	0	0	0
					7	332	645421	645840	1	0	0
					7	332	645841	646060	1	1	0
					7	332	646061	647020	1	1	1
					7	332	647021	647440	0	1	1
					7	332	647441	647660	0	0	1
					7	332	647661	648500	0	0	0
					7	332	648501	648960	20	0	0
					7	332	648961	649200	20	1	0
					7	332	649201	650080	20	1	1
					7	332	650081	650560	0	1	1
					7	332	650561	650780	0	0	1
					7	332	650781	651560	0	0	0
					7	332	651561	652100	1	0	0
					7	332	652101	652320	1	20	0
					7	332	652321	653160	1	20	20
					7	332	653161	653680	0	20	20
					7	332	653681	653920	0	0	20
					7	332	653921	654640	0	0	0
					7	332	654641	655220	1	0	0
					7	332	655221	655440	1	1	0
					7	332	655441	656240	1	1	1
					7	332	656241	656820	0	1	1
					7	332	656821	657040	0	0	1
					7	332	657041	657720	0	0	0
					7	332	657721	658340	20	0	0
					7	332	658341	658560	20	1	0
					7	332	658561	659320	20	1	1
					7	332	659321	659940	0	1	1
					7	332	659941	660160	0	0	1
					7	332	660161	660800	0	0	0
					7	332	660801	661460	1	0	0
					7	332	661461	661700	1	20	0
					7	332	661701	662400	1	20	20
					7	332	662401	663060	0	20	20
					7	332	663061	663280	0	0	20
					7	332	663281	663880	0	0	0
					7	332	663881	664580	1	0	0
					7	332	664581	664820	1	1	0
					7	332	664821	665480	1	1	1
					7	332	665481	666180	0	1	1
					7	332	666181	666420	0	0	1
					7	332	666421	666960	0	0	0
					7	332	666961	667700	20	0	0
					7	332	667701	667940	20	1	0
					7	332	667941	668560	20	1	1
					7	332	668561	669300	0	1	1
					7	332	669301	669540	0	0	1
					7	332	669541	670040	0	0	0
					7	332	670041	670820	1	0	0
					7	332	670821	671060	1	20	0
					7	332	671061	671640	1	20	20
					7	332	671641	672420	0	20	20
					7	332	672421	672660	0	0	20
					7	332	672661	673120	0	0	0
					7	332	673121	673940	1	0	0
					7	332	673941	674200	1	1	0
					7	332	674201	674720	1	1	1
					7	332	674721	675540	0	1	1
					7	332	675541	675780	0	0	1
					7	332	675781	676200	0	0	0
					7	332	676201	677060	20	0	0
					7	332	677061	677320	20	1	0
					7	332	677321	677780	20	1	1
					7	332	677781	678660	0	1	1
					7	332	678661	678920	0	0	1
					7	332	678921	679260	0	0	0
					7	332	679261	680000	1	0	0
					7	333	620000	620800	0	0	0
					7	333	620801	620860	20	0	0
					7	333	620861	621060	20	1	0
					7	333	621061	622380	20	1	1
					7	333	622381	622460	0	1	1
					7	333	622461	622660	0	0	1
					7	333	622661	623860	0	0	0
					7	333	623861	624000	1	0	0
					7	333	624001	624200	1	20	0
					7	333	624201	625460	1	20	20
					7	333	625461	625580	0	20	20
					7	333	625581	625780	0	0	20
					7	333	625781	626940	0	0	0
					7	333	626941	627120	1	0	0
					7	333	627121	627320	1	1	0
					7	333	627321	628540	1	1	1
					7	333	628541	628720	0	1	1
					7	333	628721	628920	0	0	1
					7	333	628921	630020	0	0	0
					7	333	630021	630240	20	0	0
					7	333	630241	630440	20	1	0
					7	333	630441	631620	20	1	1
					7	333	631621	631840	0	1	1
					7	333	631841	632040	0	0	1
					7	333	632041	633100	0	0	0
					7	333	633101	633360	1	0	0
					7	333	633361	633560	1	20	0
					7	333	633561	634700	1	20	20
					7	333	634701	634960	0	20	20
					7	333	634961	635160	0	0	20
					7	333	635161	636180	0	0	0
					7	333	636181	636480	1	0	0
					7	333	636481	636700	1	1	0
					7	333	636701	637780	1	1	1
					7	333	637781	638080	0	1	1
					7	333	638081	638280	0	0	1
					7	333	638281	639260	0	0	0
					7	333	639261	639600	20	0	0
					7	333	639601	639820	20	1	0
					7	333	639821	640860	20	1	1
					7	333	640861	641200	0	1	1
					7	333	641201	641420	0	0	1
					7	333	641421	642340	0	0	0
					7	333	642341	642720	1	0	0
					7	333	642721	642940	1	20	0
					7	333	642941	643940	1	20	20
					7	333	643941	644320	0	20	20
					7	333	644321	644540	0	0	20
					7	333	644541	645420	0	0	0
					7	333	645421	645840	1	0	0
					7	333	645841	646060	1	1	0
					7	333	646061	647020	1	1	1
					7	333	647021	647440	0	1	1
					7	333	647441	647660	0	0	1
					7	333	647661	648500	0	0	0
					7	333	648501	648960	20	0	0
					7	333	648961	649200	20	1	0
					7	333	649201	650080	20	1	1
					7	333	650081	650560	0	1	1
					7	333	650561	650780	0	0	1
					7	333	650781	651560	0	0	0
					7	333	651561	652100	1	0	0
					7	333	652101	652320	1	20	0
					7	333	652321	653160	1	20	20
					7	333	653161	653333	0	20	20
					7	334	693334	694274	0	1	1
					7	334	694275	694534	0	0	1
					7	334	694535	694654	0	0	0
					7	334	694655	695794	20	0	0
					7	334	695795	696074	20	1	0
					7	334	696075	696254	20	1	1
					7	334	696255	697394	0	1	1
					7	334	697395	697674	0	0	1
					7	334	697675	697734	0	0	0
					7	334	697735	698934	1	0	0
					7	334	698935	699194	1	20	0
					7	334	699195	699334	1	20	20
					7	334	699335	700514	0	20	20
					7	334	700515	700794	0	0	20
					7	334	700795	700814	0	0	0
					7	334	700815	702054	1	0	0
					7	334	702055	702314	1	1	0
					7	334	702315	702414	1	1	1
					7	334	702415	703654	0	1	1
					7	334	703655	703894	0	0	1
					7	334	703895	703914	20	0	1
					7	334	703915	705174	20	0	0
					7	334	705175	705434	20	1	0
					7	334	705435	705494	20	1	1
					7	334	705495	706774	0	1	1
					7	334	706775	706974	0	0	1
					7	334	706975	707034	1	0	1
					7	334	707035	708294	1	0	0
					7	334	708295	708574	1	20	0
					7	334	708575	709894	0	20	20
					7	334	709895	710054	0	0	20
					7	334	710055	710174	1	0	20
					7	334	710175	711414	1	0	0
					7	334	711415	711654	1	1	0
					7	334	711655	711694	0	1	0
					7	334	711695	713014	0	1	1
					7	334	713015	713134	0	0	1
					7	334	713135	713294	20	0	1
					7	334	713295	714534	20	0	0
					7	334	714535	714714	20	1	0
					7	334	714715	714814	0	1	0
					7	334	714815	716134	0	1	1
					7	334	716135	716194	0	0	1
					7	334	716195	716414	1	0	1
					7	334	716415	717654	1	0	0
					7	334	717655	717794	1	20	0
					7	334	717795	717934	0	20	0
					7	334	717935	719254	0	20	20
					7	334	719255	719274	0	0	20
					7	334	719275	719534	1	0	20
					7	334	719535	720774	1	0	0
					7	334	720775	720874	1	1	0
					7	334	720875	721074	0	1	0
					7	334	721075	722354	0	1	1
					7	334	722355	722374	20	1	1
					7	334	722375	722674	20	0	1
					7	334	722675	723894	20	0	0
					7	334	723895	723954	20	1	0
					7	334	723955	724194	0	1	0
					7	334	724195	725434	0	1	1
					7	334	725435	725494	1	1	1
					7	334	725495	725794	1	0	1
					7	334	725795	727034	1	0	0
					7	334	727035	727314	0	20	0
					7	334	727315	728514	0	20	20
					7	334	728515	728614	1	20	20
					7	334	728615	728914	1	0	20
					7	334	728915	730114	1	0	0
					7	334	730115	730154	0	0	0
					7	334	730155	730434	0	1	0
					7	334	730435	731594	0	1	1
					7	334	731595	731754	20	1	1
					7	334	731755	732034	20	0	1
					7	334	732035	733194	20	0	0
					7	334	733195	733274	0	0	0
					7	334	733275	733333	0	1	0
				>;
			};
		};
	};
};
